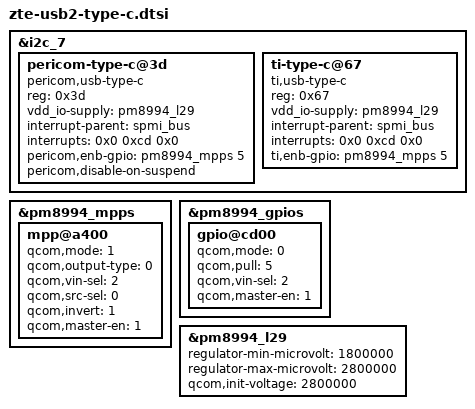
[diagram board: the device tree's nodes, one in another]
/*
 * Copyright (c) 2015 The Linux Foundation. All rights reserved.
 *
 * This program is free software; you can redistribute it and/or modify
 * it under the terms of the GNU General Public License version 2 and
 * only version 2 as published by the Free Software Foundation.
 *
 * This program is distributed in the hope that it will be useful,
 * but WITHOUT ANY WARRANTY; without even the implied warranty of
 * MERCHANTABILITY or FITNESS FOR A PARTICULAR PURPOSE.  See the
 * GNU General Public License for more details.
 */

/* Segment 1: Type-C Chips main DTS config */
&i2c_7 {

	pericom-type-c@3d {
		compatible = "pericom,usb-type-c";
		reg = <0x3d>;
		vdd_io-supply = <&pm8994_l29>;
		interrupt-parent = <&spmi_bus>;
		interrupts = <0x0 0xcd 0x0>;  /* PM8994 14, TRIGGER_FALLING */
		pericom,enb-gpio = <&pm8994_mpps 5 0x0>;/* active high */
		pericom,disable-on-suspend;
	};

	ti-type-c@67 {
		compatible = "ti,usb-type-c";
		reg = <0x67>;
		vdd_io-supply = <&pm8994_l29>;
		interrupt-parent = <&spmi_bus>;
		interrupts = <0x0 0xcd 0x0>;  /* PM8994 14, TRIGGER_FALLING */
		ti,enb-gpio = <&pm8994_mpps 5 0x0>;  /* active high */
	};
};

/* Segment 2: Type-C related PM MPP config */
&pm8994_mpps {
	mpp@a400 {	/* MPP 5 */
		/* type-c cc en and 3.0 mux enable */
		qcom,mode = <1>;	/* Digital output */
		qcom,output-type = <0>;	/* CMOS logic */
		qcom,vin-sel = <2>;	/* QPNP_PIN_VIN0 */
		qcom,src-sel = <0>;	/* QPNP_PIN_SEL_FUNC_CONSTANT */
		qcom,invert = <1>;	/* MPP Enable */
		qcom,master-en = <1>;	/* Enable */
		status = "okay";
	};
};

/* Segment 3: Type-C related PM GPIO config */
&pm8994_gpios {
	gpio@cd00 {	/* GPIO 14 */
		/* TYPEC_INT_N CC Interrupt*/
		qcom,mode = <0>;	/* Digital input */
		qcom,pull = <5>;	/* No Pull */
		qcom,vin-sel = <2>;
		qcom,master-en = <1>;	/* Enable */
		status = "okay";
	};
};

&pm8994_l29 {
	regulator-min-microvolt = <1800000>;
	regulator-max-microvolt = <2800000>;
	qcom,init-voltage = <2800000>;
};
